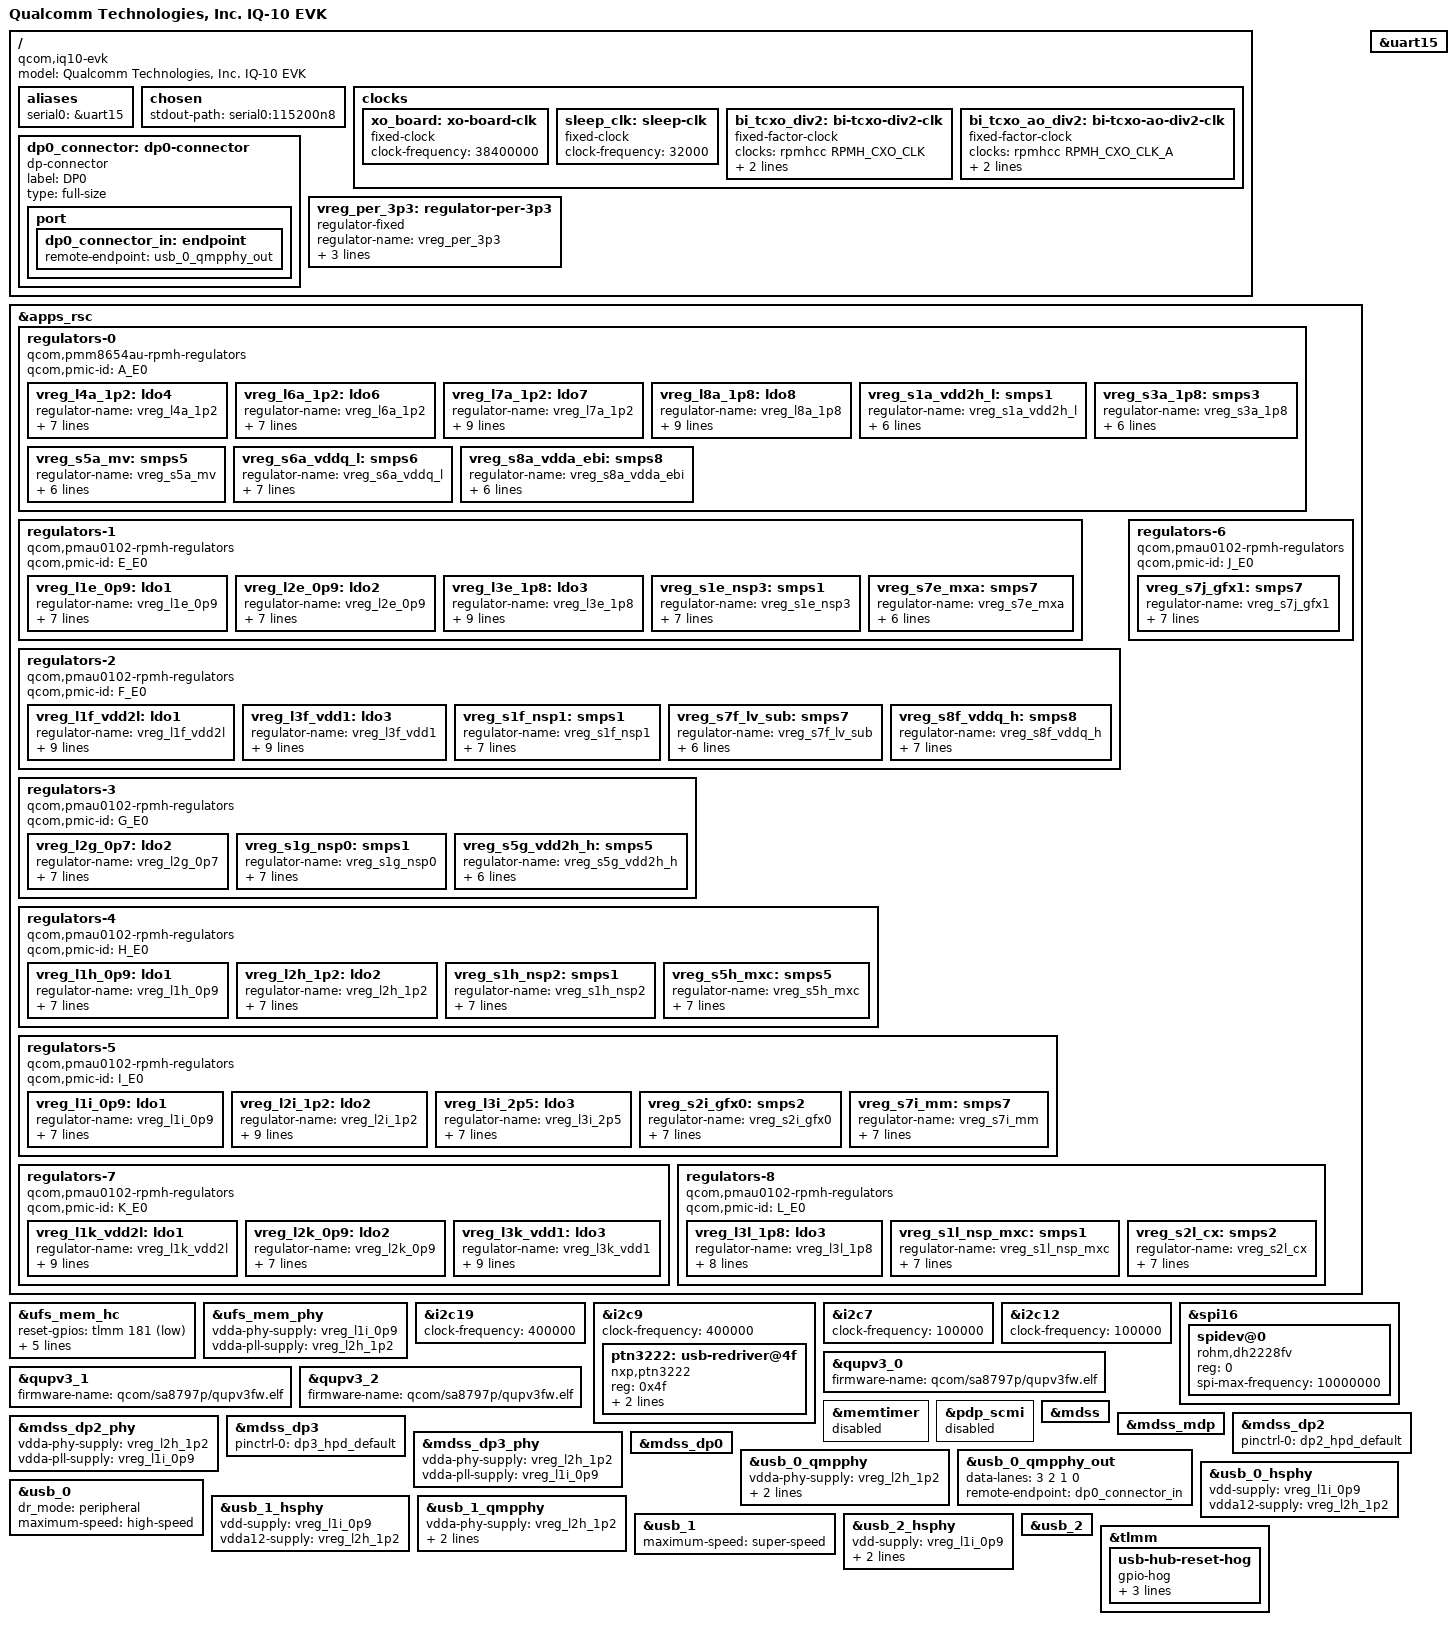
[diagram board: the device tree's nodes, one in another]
// SPDX-License-Identifier: BSD-3-Clause
/*
 * Copyright (c) 2024-2025, Qualcomm Innovation Center, Inc. All rights reserved.
 */

/dts-v1/;

#include <dt-bindings/gpio/gpio.h>
#include <dt-bindings/regulator/qcom,rpmh-regulator.h>

#include "nord-iq10.dtsi"

/ {
	model = "Qualcomm Technologies, Inc. IQ-10 EVK";
	compatible = "qcom,iq10-evk", "qcom,iq10", "qcom,nord";

	aliases {
		serial0 = &uart15;
	};

	chosen {
		stdout-path = "serial0:115200n8";
	};

	clocks {
		xo_board: xo-board-clk {
			compatible = "fixed-clock";
			clock-frequency = <38400000>;
			#clock-cells = <0>;
		};

		sleep_clk: sleep-clk {
			compatible = "fixed-clock";
			clock-frequency = <32000>;
			#clock-cells = <0>;
		};

		bi_tcxo_div2: bi-tcxo-div2-clk {
			compatible = "fixed-factor-clock";
			#clock-cells = <0>;
			clocks = <&rpmhcc RPMH_CXO_CLK>;
			clock-mult = <1>;
			clock-div = <2>;
		};

		bi_tcxo_ao_div2: bi-tcxo-ao-div2-clk {
			compatible = "fixed-factor-clock";
			#clock-cells = <0>;
			clocks = <&rpmhcc RPMH_CXO_CLK_A>;
			clock-mult = <1>;
			clock-div = <2>;
		};
	};

	/*
	 * Static full-size DisplayPort connector on JDP0.  The combo QMP
	 * PHY registers a transparent DP aux-bridge whose downstream bridge
	 * is taken from the PHY port@0 endpoint; this dp-connector provides
	 * that drm_bridge without pmic_glink / Type-C PD negotiation.  HPD
	 * is sourced from the DP controller's internal HPD block, as on
	 * DP2/DP3.
	 */
	dp0_connector: dp0-connector {
		compatible = "dp-connector";
		label = "DP0";
		type = "full-size";

		port {
			dp0_connector_in: endpoint {
				remote-endpoint = <&usb_0_qmpphy_out>;
			};
		};
	};
};

&apps_rsc {
	/* PMIC A - Kobra_MM (PMM8650AU) - SID 0x0, Bus E0 */
	regulators-0 {
		compatible = "qcom,pmm8654au-rpmh-regulators";
		qcom,pmic-id = "A_E0";

		/* LDO Regulators */
		vreg_l4a_1p2: ldo4 {
			regulator-name = "vreg_l4a_1p2";
			regulator-min-microvolt = <1200000>;
			regulator-max-microvolt = <1200000>;
			regulator-initial-mode = <RPMH_REGULATOR_MODE_HPM>;
			regulator-allow-set-load;
			regulator-allowed-modes = <RPMH_REGULATOR_MODE_LPM
						   RPMH_REGULATOR_MODE_HPM>;
		};

		vreg_l6a_1p2: ldo6 {
			regulator-name = "vreg_l6a_1p2";
			regulator-min-microvolt = <1200000>;
			regulator-max-microvolt = <1200000>;
			regulator-initial-mode = <RPMH_REGULATOR_MODE_HPM>;
			regulator-allow-set-load;
			regulator-allowed-modes = <RPMH_REGULATOR_MODE_LPM
						   RPMH_REGULATOR_MODE_HPM>;
		};

		vreg_l7a_1p2: ldo7 {
			regulator-name = "vreg_l7a_1p2";
			regulator-min-microvolt = <1200000>;
			regulator-max-microvolt = <1200000>;
			regulator-initial-mode = <RPMH_REGULATOR_MODE_HPM>;
			regulator-always-on;
			regulator-boot-on;
			regulator-allow-set-load;
			regulator-allowed-modes = <RPMH_REGULATOR_MODE_LPM
						   RPMH_REGULATOR_MODE_HPM>;
		};

		vreg_l8a_1p8: ldo8 {
			regulator-name = "vreg_l8a_1p8";
			regulator-min-microvolt = <1800000>;
			regulator-max-microvolt = <1800000>;
			regulator-initial-mode = <RPMH_REGULATOR_MODE_HPM>;
			regulator-always-on;
			regulator-boot-on;
			regulator-allow-set-load;
			regulator-allowed-modes = <RPMH_REGULATOR_MODE_LPM
						   RPMH_REGULATOR_MODE_HPM>;
		};

		/* SMPS Regulators */
		vreg_s1a_vdd2h_l: smps1 {
			regulator-name = "vreg_s1a_vdd2h_l";
			regulator-min-microvolt = <900000>;
			regulator-max-microvolt = <1100000>;
			regulator-initial-mode = <RPMH_REGULATOR_MODE_HPM>;
			regulator-always-on;
			regulator-boot-on;
		};

		vreg_s3a_1p8: smps3 {
			regulator-name = "vreg_s3a_1p8";
			regulator-min-microvolt = <1800000>;
			regulator-max-microvolt = <1800000>;
			regulator-initial-mode = <RPMH_REGULATOR_MODE_HPM>;
			regulator-always-on;
			regulator-boot-on;
		};

		vreg_s5a_mv: smps5 {
			regulator-name = "vreg_s5a_mv";
			regulator-min-microvolt = <1328000>;
			regulator-max-microvolt = <1370000>;
			regulator-initial-mode = <RPMH_REGULATOR_MODE_HPM>;
			regulator-always-on;
			regulator-boot-on;
		};

		vreg_s6a_vddq_l: smps6 {
			regulator-name = "vreg_s6a_vddq_l";
			regulator-min-microvolt = <500000>;
			regulator-max-microvolt = <570000>;
			regulator-initial-mode = <RPMH_REGULATOR_MODE_HPM>;
			regulator-allow-set-load;
			regulator-allowed-modes = <RPMH_REGULATOR_MODE_LPM
						   RPMH_REGULATOR_MODE_HPM>;
		};

		vreg_s8a_vdda_ebi: smps8 {
			regulator-name = "vreg_s8a_vdda_ebi";
			regulator-min-microvolt = <300000>;
			regulator-max-microvolt = <1200000>;
			regulator-initial-mode = <RPMH_REGULATOR_MODE_HPM>;
			regulator-always-on;
			regulator-boot-on;
		};
	};

	/* PMIC E - Kai_MV - SID 0x4, Bus E0 */
	regulators-1 {
		compatible = "qcom,pmau0102-rpmh-regulators";
		qcom,pmic-id = "E_E0";

		/* LDO Regulators */
		vreg_l1e_0p9: ldo1 {
			regulator-name = "vreg_l1e_0p9";
			regulator-min-microvolt = <936000>;
			regulator-max-microvolt = <936000>;
			regulator-initial-mode = <RPMH_REGULATOR_MODE_HPM>;
			regulator-allow-set-load;
			regulator-allowed-modes = <RPMH_REGULATOR_MODE_LPM
						   RPMH_REGULATOR_MODE_HPM>;
		};

		vreg_l2e_0p9: ldo2 {
			regulator-name = "vreg_l2e_0p9";
			regulator-min-microvolt = <936000>;
			regulator-max-microvolt = <936000>;
			regulator-initial-mode = <RPMH_REGULATOR_MODE_HPM>;
			regulator-allow-set-load;
			regulator-allowed-modes = <RPMH_REGULATOR_MODE_LPM
						   RPMH_REGULATOR_MODE_HPM>;
		};

		vreg_l3e_1p8: ldo3 {
			regulator-name = "vreg_l3e_1p8";
			regulator-min-microvolt = <1800000>;
			regulator-max-microvolt = <1800000>;
			regulator-initial-mode = <RPMH_REGULATOR_MODE_HPM>;
			regulator-always-on;
			regulator-boot-on;
			regulator-allow-set-load;
			regulator-allowed-modes = <RPMH_REGULATOR_MODE_LPM
						   RPMH_REGULATOR_MODE_HPM>;
		};

		/* SMPS Regulators */
		vreg_s1e_nsp3: smps1 {
			regulator-name = "vreg_s1e_nsp3";
			regulator-min-microvolt = <300000>;
			regulator-max-microvolt = <1200000>;
			regulator-initial-mode = <RPMH_REGULATOR_MODE_HPM>;
			regulator-allow-set-load;
			regulator-allowed-modes = <RPMH_REGULATOR_MODE_LPM
						   RPMH_REGULATOR_MODE_HPM>;
		};

		vreg_s7e_mxa: smps7 {
			regulator-name = "vreg_s7e_mxa";
			regulator-min-microvolt = <300000>;
			regulator-max-microvolt = <1200000>;
			regulator-initial-mode = <RPMH_REGULATOR_MODE_HPM>;
			regulator-always-on;
			regulator-boot-on;
		};
	};

	/* PMIC F - Kai_MV - SID 0x5, Bus E0 */
	regulators-2 {
		compatible = "qcom,pmau0102-rpmh-regulators";
		qcom,pmic-id = "F_E0";

		/* LDO Regulators */
		vreg_l1f_vdd2l: ldo1 {
			regulator-name = "vreg_l1f_vdd2l";
			regulator-min-microvolt = <904000>;
			regulator-max-microvolt = <904000>;
			regulator-initial-mode = <RPMH_REGULATOR_MODE_HPM>;
			regulator-always-on;
			regulator-boot-on;
			regulator-allow-set-load;
			regulator-allowed-modes = <RPMH_REGULATOR_MODE_LPM
						   RPMH_REGULATOR_MODE_HPM>;
		};

		vreg_l3f_vdd1: ldo3 {
			regulator-name = "vreg_l3f_vdd1";
			regulator-min-microvolt = <1800000>;
			regulator-max-microvolt = <1800000>;
			regulator-initial-mode = <RPMH_REGULATOR_MODE_HPM>;
			regulator-always-on;
			regulator-boot-on;
			regulator-allow-set-load;
			regulator-allowed-modes = <RPMH_REGULATOR_MODE_LPM
						   RPMH_REGULATOR_MODE_HPM>;
		};

		/* SMPS Regulators */
		vreg_s1f_nsp1: smps1 {
			regulator-name = "vreg_s1f_nsp1";
			regulator-min-microvolt = <300000>;
			regulator-max-microvolt = <1200000>;
			regulator-initial-mode = <RPMH_REGULATOR_MODE_HPM>;
			regulator-allow-set-load;
			regulator-allowed-modes = <RPMH_REGULATOR_MODE_LPM
						   RPMH_REGULATOR_MODE_HPM>;
		};

		vreg_s7f_lv_sub: smps7 {
			regulator-name = "vreg_s7f_lv_sub";
			regulator-min-microvolt = <1036000>;
			regulator-max-microvolt = <1136000>;
			regulator-initial-mode = <RPMH_REGULATOR_MODE_HPM>;
			regulator-always-on;
			regulator-boot-on;
		};

		vreg_s8f_vddq_h: smps8 {
			regulator-name = "vreg_s8f_vddq_h";
			regulator-min-microvolt = <500000>;
			regulator-max-microvolt = <570000>;
			regulator-initial-mode = <RPMH_REGULATOR_MODE_HPM>;
			regulator-allow-set-load;
			regulator-allowed-modes = <RPMH_REGULATOR_MODE_LPM
						   RPMH_REGULATOR_MODE_HPM>;
		};
	};

	/* PMIC G - Kai_MV - SID 0x6, Bus E0 */
	regulators-3 {
		compatible = "qcom,pmau0102-rpmh-regulators";
		qcom,pmic-id = "G_E0";

		/* LDO Regulators */
		vreg_l2g_0p7: ldo2 {
			regulator-name = "vreg_l2g_0p7";
			regulator-min-microvolt = <752000>;
			regulator-max-microvolt = <752000>;
			regulator-initial-mode = <RPMH_REGULATOR_MODE_HPM>;
			regulator-allow-set-load;
			regulator-allowed-modes = <RPMH_REGULATOR_MODE_LPM
						   RPMH_REGULATOR_MODE_HPM>;
		};

		/* SMPS Regulators */
		vreg_s1g_nsp0: smps1 {
			regulator-name = "vreg_s1g_nsp0";
			regulator-min-microvolt = <300000>;
			regulator-max-microvolt = <1200000>;
			regulator-initial-mode = <RPMH_REGULATOR_MODE_HPM>;
			regulator-allow-set-load;
			regulator-allowed-modes = <RPMH_REGULATOR_MODE_LPM
						   RPMH_REGULATOR_MODE_HPM>;
		};

		vreg_s5g_vdd2h_h: smps5 {
			regulator-name = "vreg_s5g_vdd2h_h";
			regulator-min-microvolt = <1080000>;
			regulator-max-microvolt = <1150000>;
			regulator-initial-mode = <RPMH_REGULATOR_MODE_HPM>;
			regulator-always-on;
			regulator-boot-on;
		};
	};

	/* PMIC H - Kai_MV - SID 0x7, Bus E0 */
	regulators-4 {
		compatible = "qcom,pmau0102-rpmh-regulators";
		qcom,pmic-id = "H_E0";

		/* LDO Regulators */
		vreg_l1h_0p9: ldo1 {
			regulator-name = "vreg_l1h_0p9";
			regulator-min-microvolt = <904000>;
			regulator-max-microvolt = <904000>;
			regulator-initial-mode = <RPMH_REGULATOR_MODE_HPM>;
			regulator-allow-set-load;
			regulator-allowed-modes = <RPMH_REGULATOR_MODE_LPM
						   RPMH_REGULATOR_MODE_HPM>;
		};

		vreg_l2h_1p2: ldo2 {
			regulator-name = "vreg_l2h_1p2";
			regulator-min-microvolt = <1200000>;
			regulator-max-microvolt = <1200000>;
			regulator-initial-mode = <RPMH_REGULATOR_MODE_HPM>;
			regulator-allow-set-load;
			regulator-allowed-modes = <RPMH_REGULATOR_MODE_LPM
						   RPMH_REGULATOR_MODE_HPM>;
		};

		/* SMPS Regulators */
		vreg_s1h_nsp2: smps1 {
			regulator-name = "vreg_s1h_nsp2";
			regulator-min-microvolt = <300000>;
			regulator-max-microvolt = <1200000>;
			regulator-initial-mode = <RPMH_REGULATOR_MODE_HPM>;
			regulator-allow-set-load;
			regulator-allowed-modes = <RPMH_REGULATOR_MODE_LPM
						   RPMH_REGULATOR_MODE_HPM>;
		};

		vreg_s5h_mxc: smps5 {
			regulator-name = "vreg_s5h_mxc";
			regulator-min-microvolt = <300000>;
			regulator-max-microvolt = <1200000>;
			regulator-initial-mode = <RPMH_REGULATOR_MODE_HPM>;
			regulator-allow-set-load;
			regulator-allowed-modes = <RPMH_REGULATOR_MODE_LPM
						   RPMH_REGULATOR_MODE_HPM>;
		};
	};

	/* PMIC I - Kai_MV - SID 0x8, Bus E0 */
	regulators-5 {
		compatible = "qcom,pmau0102-rpmh-regulators";
		qcom,pmic-id = "I_E0";

		/* LDO Regulators */
		vreg_l1i_0p9: ldo1 {
			regulator-name = "vreg_l1i_0p9";
			regulator-min-microvolt = <912000>;
			regulator-max-microvolt = <912000>;
			regulator-initial-mode = <RPMH_REGULATOR_MODE_HPM>;
			regulator-allow-set-load;
			regulator-allowed-modes = <RPMH_REGULATOR_MODE_LPM
						   RPMH_REGULATOR_MODE_HPM>;
		};

		vreg_l2i_1p2: ldo2 {
			regulator-name = "vreg_l2i_1p2";
			regulator-min-microvolt = <1200000>;
			regulator-max-microvolt = <1200000>;
			regulator-initial-mode = <RPMH_REGULATOR_MODE_HPM>;
			regulator-always-on;
			regulator-boot-on;
			regulator-allow-set-load;
			regulator-allowed-modes = <RPMH_REGULATOR_MODE_LPM
						   RPMH_REGULATOR_MODE_HPM>;
		};

		vreg_l3i_2p5: ldo3 {
			regulator-name = "vreg_l3i_2p5";
			regulator-min-microvolt = <2504000>;
			regulator-max-microvolt = <2504000>;
			regulator-initial-mode = <RPMH_REGULATOR_MODE_HPM>;
			regulator-allow-set-load;
			regulator-allowed-modes = <RPMH_REGULATOR_MODE_LPM
						   RPMH_REGULATOR_MODE_HPM>;
		};

		/* SMPS Regulators */
		vreg_s2i_gfx0: smps2 {
			regulator-name = "vreg_s2i_gfx0";
			regulator-min-microvolt = <300000>;
			regulator-max-microvolt = <1200000>;
			regulator-initial-mode = <RPMH_REGULATOR_MODE_HPM>;
			regulator-allow-set-load;
			regulator-allowed-modes = <RPMH_REGULATOR_MODE_LPM
						   RPMH_REGULATOR_MODE_HPM>;
		};

		vreg_s7i_mm: smps7 {
			regulator-name = "vreg_s7i_mm";
			regulator-min-microvolt = <300000>;
			regulator-max-microvolt = <1200000>;
			regulator-initial-mode = <RPMH_REGULATOR_MODE_HPM>;
			regulator-allow-set-load;
			regulator-allowed-modes = <RPMH_REGULATOR_MODE_LPM
						   RPMH_REGULATOR_MODE_HPM>;
		};
	};

	/* PMIC J - Kai_MV - SID 0x9, Bus E0 */
	regulators-6 {
		compatible = "qcom,pmau0102-rpmh-regulators";
		qcom,pmic-id = "J_E0";

		/* SMPS Regulators */
		vreg_s7j_gfx1: smps7 {
			regulator-name = "vreg_s7j_gfx1";
			regulator-min-microvolt = <300000>;
			regulator-max-microvolt = <1200000>;
			regulator-initial-mode = <RPMH_REGULATOR_MODE_HPM>;
			regulator-allow-set-load;
			regulator-allowed-modes = <RPMH_REGULATOR_MODE_LPM
						   RPMH_REGULATOR_MODE_HPM>;
		};
	};

	/* PMIC K - Kai_MV - SID 0xA, Bus E0 */
	regulators-7 {
		compatible = "qcom,pmau0102-rpmh-regulators";
		qcom,pmic-id = "K_E0";

		/* LDO Regulators */
		vreg_l1k_vdd2l: ldo1 {
			regulator-name = "vreg_l1k_vdd2l";
			regulator-min-microvolt = <904000>;
			regulator-max-microvolt = <904000>;
			regulator-initial-mode = <RPMH_REGULATOR_MODE_HPM>;
			regulator-always-on;
			regulator-boot-on;
			regulator-allow-set-load;
			regulator-allowed-modes = <RPMH_REGULATOR_MODE_LPM
						   RPMH_REGULATOR_MODE_HPM>;
		};

		vreg_l2k_0p9: ldo2 {
			regulator-name = "vreg_l2k_0p9";
			regulator-min-microvolt = <880000>;
			regulator-max-microvolt = <880000>;
			regulator-initial-mode = <RPMH_REGULATOR_MODE_HPM>;
			regulator-allow-set-load;
			regulator-allowed-modes = <RPMH_REGULATOR_MODE_LPM
						   RPMH_REGULATOR_MODE_HPM>;
		};

		vreg_l3k_vdd1: ldo3 {
			regulator-name = "vreg_l3k_vdd1";
			regulator-min-microvolt = <1800000>;
			regulator-max-microvolt = <1800000>;
			regulator-initial-mode = <RPMH_REGULATOR_MODE_HPM>;
			regulator-always-on;
			regulator-boot-on;
			regulator-allow-set-load;
			regulator-allowed-modes = <RPMH_REGULATOR_MODE_LPM
						   RPMH_REGULATOR_MODE_HPM>;
		};
	};

	/* PMIC L - Kai_MV - SID 0xB, Bus E0 */
	regulators-8 {
		compatible = "qcom,pmau0102-rpmh-regulators";
		qcom,pmic-id = "L_E0";

		/* LDO Regulators */
		vreg_l3l_1p8: ldo3 {
			regulator-name = "vreg_l3l_1p8";
			regulator-min-microvolt = <1800000>;
			regulator-max-microvolt = <1800000>;
			/* VDD_EUSB_1P8: the PTN3222 (U14) 1.8V.  Always-on for bring-up
			 * so the redriver stays powered even if its I2C address guess is
			 * wrong, letting i2cdetect find the real one. */
			regulator-always-on;
			regulator-initial-mode = <RPMH_REGULATOR_MODE_HPM>;
			regulator-allow-set-load;
			regulator-allowed-modes = <RPMH_REGULATOR_MODE_LPM
						   RPMH_REGULATOR_MODE_HPM>;
		};

		/* SMPS Regulators */
		vreg_s1l_nsp_mxc: smps1 {
			regulator-name = "vreg_s1l_nsp_mxc";
			regulator-min-microvolt = <300000>;
			regulator-max-microvolt = <1200000>;
			regulator-initial-mode = <RPMH_REGULATOR_MODE_HPM>;
			regulator-allow-set-load;
			regulator-allowed-modes = <RPMH_REGULATOR_MODE_LPM
						   RPMH_REGULATOR_MODE_HPM>;
		};

		vreg_s2l_cx: smps2 {
			regulator-name = "vreg_s2l_cx";
			regulator-min-microvolt = <300000>;
			regulator-max-microvolt = <1200000>;
			regulator-initial-mode = <RPMH_REGULATOR_MODE_HPM>;
			regulator-allow-set-load;
			regulator-allowed-modes = <RPMH_REGULATOR_MODE_LPM
						   RPMH_REGULATOR_MODE_HPM>;
		};
	};
};

&uart15 {
	status = "okay";
};

&ufs_mem_hc {
	reset-gpios = <&tlmm 181 GPIO_ACTIVE_LOW>;

	/* UFS controller-island power via OP-TEE SCMI (SCMI-over-FF-A, 0x11) */
	power-domains = <&scmi_optee_pd 0>;

	vcc-supply = <&vreg_l3i_2p5>;
	vcc-max-microamp = <1300000>;
	vccq-supply = <&vreg_l2i_1p2>;
	vccq-max-microamp = <1200000>;
	status = "okay";
};

&ufs_mem_phy {
	vdda-phy-supply = <&vreg_l1i_0p9>;
	vdda-pll-supply = <&vreg_l2h_1p2>;
	status = "okay";
};

/* === IQ-10 EVK i2c/spi enablement (sensor discovery + spidev) === */
&i2c19 { clock-frequency = <400000>; status = "okay"; };   /* IPCAT: SENSOR & power-monitor I2C (gpio156/157) */
/* VREG_PER_5P0's 3.3V sibling - the peripheral 3.3V the QAM carrier provides
 * (carrier UART: "Enabled MAIN VREG 3P3 ... 3.29 V").  Modeled as an always-on
 * fixed regulator so the PTN3222 redriver's vdd3v3 has a real supply handle. */
/ {
	vreg_per_3p3: regulator-per-3p3 {
		compatible = "regulator-fixed";
		regulator-name = "vreg_per_3p3";
		regulator-min-microvolt = <3300000>;
		regulator-max-microvolt = <3300000>;
		regulator-always-on;
	};
};

&i2c9 {
	clock-frequency = <400000>;   /* IPCAT: USB-PD/eUSB repeater & SMBus (gpio127/128) */
	status = "okay";

	/*
	 * U14: NXP PTN3222 eUSB2->USB2 redriver for the JUSB2 Type-A jack (usb_2).
	 * Without it the SoC eUSB2 signal never reaches a standard USB2 device -
	 * the port sees a connect but "unable to enumerate".  The m31 eUSB2 PHY
	 * inits this as its optional repeater phy (usb_2_hsphy phys=<&ptn3222>).
	 * Supplies (schematic sch440 U14): VDD1V8=vreg_l3l_1p8, VDD3V3=VREG_PER_3P3.
	 * RST_N = PML_GPIO_03, kept released by the pmicb eusb2_typea_reset hog.
	 * NOTE: reg 0x4f is a first guess; once powered, confirm the real address
	 * with `i2cdetect -y 2` and correct it here.
	 */
	ptn3222: usb-redriver@4f {
		compatible = "nxp,ptn3222";
		reg = <0x4f>;
		vdd3v3-supply = <&vreg_per_3p3>;
		vdd1v8-supply = <&vreg_l3l_1p8>;
		#phy-cells = <0>;
	};
};
&i2c7  { clock-frequency = <100000>; status = "okay"; };   /* DP1 DDC/AUX (gpio123/124) */
&i2c12 { clock-frequency = <100000>; status = "okay"; };   /* DP0 DDC/AUX (gpio133-136) */

&spi16 {                                                   /* qup0_se2, gpio145/146/147/148 */
	#address-cells = <1>;
	#size-cells = <0>;
	status = "okay";
	spidev@0 {
		compatible = "rohm,dh2228fv";
		reg = <0>;
		spi-max-frequency = <10000000>;
	};
};

/* GENI QUP serial-engine firmware (geni_load_se_firmware reads firmware-name from the wrapper) */
&qupv3_0 { firmware-name = "qcom/sa8797p/qupv3fw.elf"; };
&qupv3_1 { firmware-name = "qcom/sa8797p/qupv3fw.elf"; };
&qupv3_2 { firmware-name = "qcom/sa8797p/qupv3fw.elf"; };

/* arch-timer-mmio (timer@17810000): probes -22; the per-CPU arch timer is the
 * primary timer and works, this memory-mapped frame is redundant + failing. */
&memtimer { status = "disabled"; };

/* Disable the pdp_scmi arm,scmi transport.  Its arm-scmi platform device
 * fails to set up the BASE protocol channel (protocol 0x10) and then
 * retries via deferred probe indefinitely, flooding the log.  Its only
 * protocol, cpu_perf (0x13), lost its last consumer when the cpu nodes
 * moved to the OP-TEE SCMI perf domain, so disabling the node loses no
 * functionality and silences the boot. */
&pdp_scmi { status = "disabled"; };

/* enable the display subsystem for first-light (DPU + DP2/DP3 outputs + DP2/DP3 PHYs) */
&mdss          { status = "okay"; };
&mdss_mdp      { status = "okay"; };
&mdss_dp2 {
	/* HPD pad: GPIO51 func edp0_hot (downstream eDP0 -> DP2) */
	pinctrl-0 = <&dp2_hpd_default>;
	pinctrl-names = "default";
	status = "okay";
};
&mdss_dp2_phy {
	/* mirror UFS PHY: pmau0102 LDOs, always-on, no RPMh stall */
	vdda-phy-supply = <&vreg_l2h_1p2>;
	vdda-pll-supply = <&vreg_l1i_0p9>;
	status = "okay";
};
&mdss_dp3 {
	/* HPD pad: GPIO52 func edp1_hot (downstream eDP1 -> DP3) */
	pinctrl-0 = <&dp3_hpd_default>;
	pinctrl-names = "default";
	status = "okay";
};
&mdss_dp3_phy {
	/* mirror UFS PHY: pmau0102 LDOs, always-on, no RPMh stall */
	vdda-phy-supply = <&vreg_l2h_1p2>;
	vdda-pll-supply = <&vreg_l1i_0p9>;
	status = "okay";
};

/* DP0: DPU INTF_0 -> mdss_dp0 -> USB-0 combo QMP PHY (DP-only) -> JDP0 */
&mdss_dp0 {
	status = "okay";
};

&usb_0_qmpphy {
	/* Schematic SOC_PWR_SERDES: VDD_A_SERDES_1P2 <- L2H (1.2V) and
	 * VDD_A_SERDES_0P9 <- L1H (0.9V), the combo PHY's dedicated SERDES
	 * rail (not L1I, the eDP/UFS 0.9V rail). */
	vdda-phy-supply = <&vreg_l2h_1p2>;
	vdda-pll-supply = <&vreg_l1h_0p9>;
	refgen-supply = <&vreg_l1h_0p9>;
	status = "okay";
};

&usb_0_qmpphy_out {
	data-lanes = <3 2 1 0>;
	remote-endpoint = <&dp0_connector_in>;
};

/* USB-0 HS PHY rails: the same always-on pmau0102 LDOs as the DP PHYs.
 * The DWC3 controller itself stays disabled until the fabric/RPMh
 * dependencies behind its interconnect votes are in place. */
&usb_0_hsphy {
	vdd-supply = <&vreg_l1i_0p9>;
	vdda12-supply = <&vreg_l2h_1p2>;
	status = "okay";
};

/*
 * USB-0 DWC3 in host mode on the JUSB0 Type-C jack (USB4200-03-A).
 *
 * VBUS: VBUS_USB0_5P0 is switched by a TPS2559 load switch (U16) whose
 * enable, VBUS0_EN_MD1P8, is driven by GPIO3 of the FUSB15201 USB-PD
 * controller (U15, on i2c9 / GPIO127-128) - there is no SoC- or
 * PMIC-GPIO-controlled path to model as a vbus-supply regulator, so
 * VBUS sourcing relies on the PD controller's own firmware policy.
 * If a plugged device stays unpowered, poke U15 over i2c9.
 *
 * Only one SS lane pair is wired to the jack (SSTXP1/SSRXP1), so
 * SuperSpeed enumerates in a single plug orientation; the flipped
 * orientation falls back to high-speed.
 */
&usb_0 {
	/*
	 * Peripheral (gadget) mode on JUSB0 (Type-C -> galagos host Type-A),
	 * reusing the flash cable as a USB-Ethernet gadget (CDC-ECM) so the
	 * open stack has a proven USB data path without the FUSB15201 PD/
	 * Type-C driver.
	 *
	 * KEEP the full PHY set (base: hs eUSB2 + usb_0_qmpphy SS): the dwc3
	 * core soft reset needs the SS PHY's pipe clock running to complete -
	 * dropping the combo phy gave "-ETIMEDOUT: failed to initialize core"
	 * (hit live).  In host mode the same PHY set inits cleanly (only the
	 * SS *link* fails on orientation); peripheral is the sole delta here.
	 * Cap at high-speed: the combo SS PHY has no CC/orientation driver so
	 * the SS *link* never trains ("unable to determine orientation") and the
	 * host's SS port sits in "Cannot enable / config error" without falling
	 * back to HS.  maximum-speed=high-speed makes the gadget advertise HS
	 * only, so it enumerates on the host's HS path.  The SS PHY stays in the
	 * phy list (base) so dwc3 core init still gets its pipe clock.
	 */
	dr_mode = "peripheral";
	maximum-speed = "high-speed";
	status = "okay";
};

/*
 * USB-1: upstream of the onboard USB hub (U13), which fans out to the
 * JUSB1 (Type-C) and JUSB2 (Type-A) jacks.  Hub reset GP170 is released
 * by the tlmm hog below; the hub sources its own per-port VBUS via
 * PWR_EN_USB_P1/P2/P3 once it enumerates.
 */
&usb_1_hsphy {
	vdd-supply = <&vreg_l1i_0p9>;
	vdda12-supply = <&vreg_l2h_1p2>;
	status = "okay";
};

&usb_1_qmpphy {
	vdda-phy-supply = <&vreg_l2h_1p2>;
	vdda-pll-supply = <&vreg_l1h_0p9>;
	refgen-supply = <&vreg_l1h_0p9>;
	status = "okay";
};

&usb_1 {
	/*
	 * usb_1 is hardwired to the onboard GL3590 hub U13 (a soldered SS
	 * link, no Type-C / no orientation switch), so it does NOT need the
	 * FUSB15201 - usb_1_qmpphy already forces USB3-only, fixed-normal
	 * orientation via data-lanes = <1 0> (nord-iq10.dtsi).  The earlier
	 * "usb3-port1: Cannot enable" was a PHY receiver-detect miss: the
	 * host never saw the hub's far-end SS receiver during LFPS detect.
	 * The vendor's authoritative V1.12 SS-PHY tuning bumps RCV_DETECT_LVL_2
	 * 0x12->0x14 (see nord_ssphy_tbl in phy-qcom-qmp-combo.c), which should
	 * let the link train.  Attempt SuperSpeed (Gen1) to validate; if it
	 * still fails to train it sits in "Cannot enable" (no HS fallback), so
	 * revert to maximum-speed = "high-speed" to keep U13 at 480 Mbps.
	 */
	maximum-speed = "super-speed";
	status = "okay";
};

/* USB-2 (usb20s): the JUSB2 Type-A jack via the PTN3222 eUSB2 repeater. */
&usb_2_hsphy {
	vdd-supply = <&vreg_l1i_0p9>;
	vdda12-supply = <&vreg_l2h_1p2>;
	/* PTN3222 redriver as the optional repeater phy: the m31 eUSB2 driver
	 * phy_init()s it, powering+configuring the eUSB2->USB2 path to JUSB2. */
	phys = <&ptn3222>;
	status = "okay";
};

&usb_2 {
	status = "okay";
};

&tlmm {
	/* GP170_USB_HUB_RESET_MD1P8_N: drive high = release hub reset. */
	usb-hub-reset-hog {
		gpio-hog;
		gpios = <170 GPIO_ACTIVE_HIGH>;
		output-high;
		line-name = "usb-hub-reset";
	};
};
